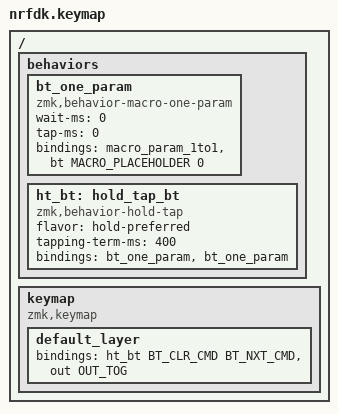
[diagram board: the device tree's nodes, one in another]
#include <behaviors.dtsi>
#include <dt-bindings/zmk/keys.h>
#include <dt-bindings/zmk/bt.h>
#include <dt-bindings/zmk/pointing.h>
#include <dt-bindings/zmk/outputs.h>

/ {
    behaviors {
        bt_one_param: bt_one_param {
            compatible = "zmk,behavior-macro-one-param";
            wait-ms = <0>;
            tap-ms = <0>;
            #binding-cells = <1>;
            bindings = <&macro_param_1to1>, <&bt MACRO_PLACEHOLDER 0>;
        };

        ht_bt: hold_tap_bt {
            compatible = "zmk,behavior-hold-tap";
            #binding-cells = <2>;
            flavor = "hold-preferred";
            tapping-term-ms = <400>;
            bindings = <&bt_one_param>, <&bt_one_param>;
        };
    };
    
    keymap {
        compatible = "zmk,keymap";

        default_layer {
            bindings = <
                &ht_bt BT_CLR_CMD BT_NXT_CMD
                &out OUT_TOG
            >;
        };
    };
};
